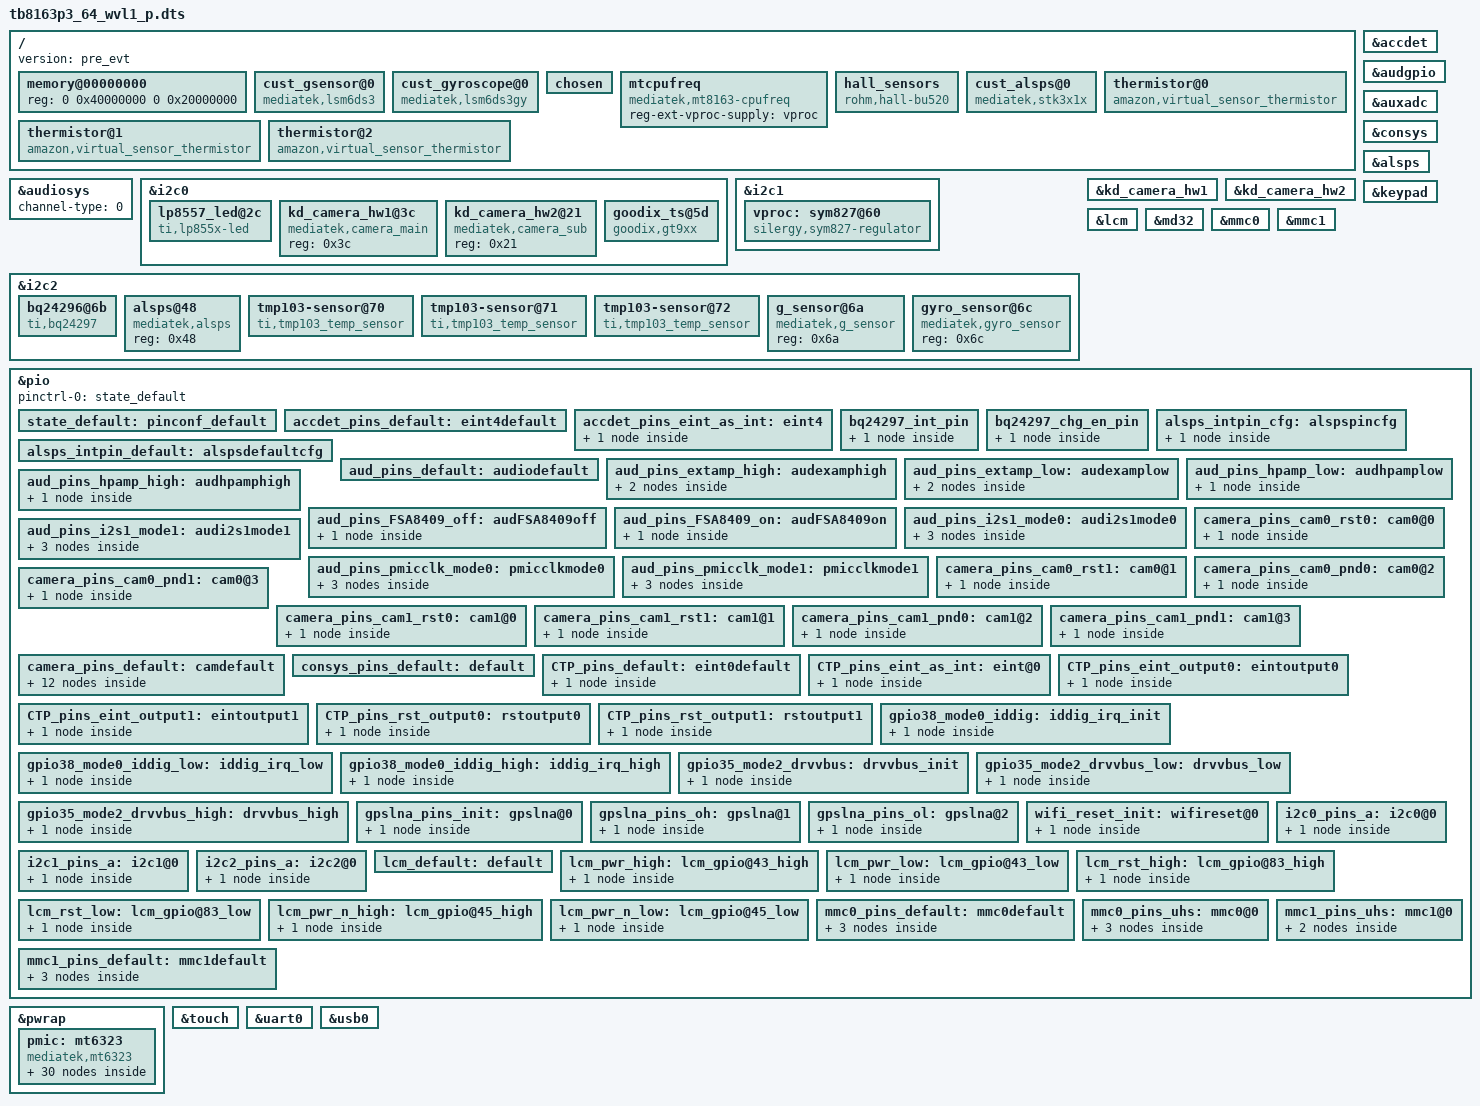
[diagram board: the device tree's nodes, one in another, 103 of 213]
/*
 * Copyright (c) 2014-2015 MediaTek Inc.
 *
 * This program is free software; you can redistribute it and/or modify
 * it under the terms of the GNU General Public License version 2 as
 * published by the Free Software Foundation.
 *
 * This program is distributed in the hope that it will be useful,
 * MERCHANTABILITY or FITNESS FOR A PARTICULAR PURPOSE.  See the
 * GNU General Public License for more details.
 */

/dts-v1/;

#include "mt8163.dtsi"
#include "tb8163p3_64_wvl1_p_bat_setting.dtsi"

/ {
	version = "pre_evt";
	memory@00000000 {
		device_type = "memory";
		reg = <0 0x40000000 0 0x20000000>;
	};

	/* Accel Sensor */
	cust_gsensor@0 {
		compatible = "mediatek,lsm6ds3";
		i2c_num = <2>;
		i2c_addr = <0x6a>;
		direction = <0>;
		power_id = <0xffff>;
		power_vol = <0>;
		firlen = <0>;
		is_batch_supported = <0>;
	};
	
	/* Gyro Sensor */
	cust_gyroscope@0 {
		compatible = "mediatek,lsm6ds3gy";
		i2c_num = <2>;
		i2c_addr = <0x6a>;
		direction = <0>;
		power_id = <0xffff>;
		power_vol = <0>;
		firlen = <0>;
		is_batch_supported = <0>;
	};

	/* chosen */
	chosen {
		bootargs = "console=ttyS0,921600n1 root=/dev/ram initrd=0x44000200,0x200000";
	};

	mtcpufreq {
		compatible = "mediatek,mt8163-cpufreq";
		reg-ext-vproc-supply = <&vproc>;
	};
	/* Hall Sensor */
	hall_sensors {
		compatible = "rohm,hall-bu520";
		interrupt-parent = <&pio>;
		interrupts = <19 IRQ_TYPE_LEVEL_LOW>;
		int-gpio = <&pio 51 0>;
		sensor-name = "hall_sensor_1";
		sensor-num = <1>;
	};
        /* ALS */
        cust_alsps@0 {
		compatible		= "mediatek,stk3x1x";
		i2c_num			= <2>;
		i2c_addr		= <0x48>;
		polling_mode_ps		= <0>;
		polling_mode_als	= <1>;
		power_id		= <0xffff>;
		power_vol		= <0>;
                /* Total has 15 level*/
		als_level	= <0 257 637 1027 2297 5588 6730 11301 20449 25768 31122 45552 57937 57937 57937>;
                /*  Total has 16 range*/
		als_value	= <0 132 304 502 1004 2003 3006 5006 8004 10000 12000 16000 20000 20000 20000 20000>;
		ps_threshold_high	= <70>;
		ps_threshold_low	= <40>;
		is_batch_supported_ps	= <1>;
	};
	/* Virtual sensor thermistor */
	thermistor@0 {
		compatible = "amazon,virtual_sensor_thermistor";
		thermistor,offset = <5250>;
		thermistor,offset.sign = "plus";
		thermistor,alpha = <10>;
		thermistor,weight = <175>;
		aux_channel_num = <0>;
	};
	thermistor@1 {
		compatible = "amazon,virtual_sensor_thermistor";
		thermistor,offset = <2900>;
		thermistor,offset.sign = "plus";
		thermistor,alpha = <10>;
		thermistor,weight = <175>;
		aux_channel_num = <1>;
	};
	thermistor@2 {
		compatible = "amazon,virtual_sensor_thermistor";
		thermistor,offset = <3000>;
		thermistor,offset.sign = "minus";
		thermistor,alpha = <10>;
		thermistor,weight = <175>;
		aux_channel_num = <2>;
	};
};

&accdet {
	interrupt-parent = <&pio>;
	interrupts = <4 IRQ_TYPE_LEVEL_LOW>;
	eint-debounce = <256000>;
	accdet-gpio = <&pio 26 0>;
	accdet-mic-vol = <7>;
	headset-mode-setting = <0x500 0x200 1 0x1f0 0x800 0x800 0x4000>;
	accdet-plugout-debounce = <1000>;
	/*1:ACC mode, 2:low cost without in bias, 6:low cost with in bias*/
	accdet-mic-mode = <1>;
	/*0--MD_MAX--UP_MAX--DW_MAX*/
	headset-three-key-threshold = <0 80 220 500>;
	/*0--MD_MAX--VOICE_MAX--UP_MAX--DW_MAX*/
	headset-four-key-threshold = <0 58 121 192 450>;
	pinctrl-names = "default", "state_eint_as_int", "typeswitchIC-off","typeswitchIC-on";
	pinctrl-0 = <&accdet_pins_default>;
	pinctrl-1 = <&accdet_pins_eint_as_int>;
	pinctrl-2 = <&aud_pins_FSA8409_off>;
	pinctrl-3 = <&aud_pins_FSA8409_on>;
	status = "okay";
};

&audiosys {
	/*0:Stereo, 1:MonoLeft, 2:MonoRight*/
	channel-type = <0>;
};

&audgpio {
	pinctrl-names = "default",
			"audpmicclk-mode0",
			"audpmicclk-mode1",
			"audi2s1-mode0",
			"audi2s1-mode1",
			"extamp-pullhigh",
			"extamp-pulllow",
			"hpamp-pullhigh",
			"hpamp-pulllow";
	pinctrl-0 = <&aud_pins_default>;
	pinctrl-1 = <&aud_pins_pmicclk_mode0>;
	pinctrl-2 = <&aud_pins_pmicclk_mode1>;
	pinctrl-3 = <&aud_pins_i2s1_mode0>;
	pinctrl-4 = <&aud_pins_i2s1_mode1>;
	pinctrl-5 = <&aud_pins_extamp_high>;
	pinctrl-6 = <&aud_pins_extamp_low>;
	pinctrl-7 = <&aud_pins_hpamp_high>;
	pinctrl-8 = <&aud_pins_hpamp_low>;
	status = "okay";
};

&auxadc {
	status = "okay";
};

&consys {
	pinctrl-names = "default",
			"gps_lna_state_init",
			"gps_lna_state_oh",
			"gps_lna_state_ol",
			"wifi_reset_init";
	pinctrl-0 = <&consys_pins_default>;
	pinctrl-1 = <&gpslna_pins_init>;
	pinctrl-2 = <&gpslna_pins_oh>;
	pinctrl-3 = <&gpslna_pins_ol>;
	pinctrl-4 = <&wifi_reset_init>;
	vcn18-supply = <&mt6323_vcn18_reg>;
	vcn28-supply = <&mt6323_vcn28_reg>;
	vcn33_bt-supply = <&mt6323_vcn33_bt_reg>;
	vcn33_wifi-supply = <&mt6323_vcn33_wifi_reg>;
	status = "okay";
};

&alsps {
	pinctrl-names = "pin_default", "pin_cfg";
	pinctrl-0 = <&alsps_intpin_default>;
	pinctrl-1 = <&alsps_intpin_cfg>;
	status = "okay";
};

&i2c0 {
	clock-frequency = <400000>;
	pinctrl-names = "default";
	pinctrl-0 = <&i2c0_pins_a>;
	status = "okay";

	lp8557_led@2c {
		compatible = "ti,lp855x-led";
		reg = <0x2c>;
		epprom_data = /bits/ 8 <0x14 0x07
					0x13 0x01
					0x11 0x05
					0x12 0x2B
					0x15 0x42
					0x16 0xA0>;
	};

	/* in cust_i2c_projXXX.dtsi ? */
	kd_camera_hw1@3c { /* Fix me to right reg val */
		compatible = "mediatek,camera_main";
		reg = <0x3c>;
	};

	/* in cust_i2c_projXXX.dtsi ? */
	kd_camera_hw2@21 { /* Fix me to right reg val */
		compatible = "mediatek,camera_sub";
		reg = <0x21>;
	};

	goodix_ts@5d {
		compatible = "goodix,gt9xx";
		reg = <0x5d>;
		pinctrl-names = "irq_as_gpio", "irq_as_int";
		pinctrl-0 = <&CTP_pins_eint_output0>;
		pinctrl-1 = <&CTP_pins_eint_as_int>;
		vdd_ana-supply = <&mt6323_vgp2_reg>;
		vcc_i2c-supply = <&mt6323_vcamaf_reg>;
		goodix,rst-gpio = <&pio 46 0x00>;
		goodix,irq-gpio = <&pio 35 0x00>;
		goodix,cfg-group0 = [
	 4B  20  03  00  05  0A  35  00  02  08
	 2D  0F  5A  32  01  04  00  00  00  00
	 13  21  00  17  18  1A  14  93  33  CC
	 58  5A  EB  17  00  00  00  22  03  1D
	 00  00  00  00  00  00  00  00  00  00
	 00  50  64  81  E2  01  14  0A  00  04
	 7A  51  00  7D  55  00  81  59  00  85
	 5D  00  8A  61  00  8A  00  00  00  00
	 00  00  00  00  00  00  00  00  00  00
	 00  00  00  00  00  00  14  00  00  00
	 00  00  00  00  00  00  00  00  00  00
	 00  00  17  16  15  14  13  12  11  10
	 0F  0E  0D  0C  0B  0A  09  08  07  06
	 05  04  03  02  01  00  FF  FF  FF  FF
	 FF  FF  00  01  02  03  04  05  06  07
	 08  09  0A  0B  0C  0E  0F  10  11  12
	 13  15  16  17  18  19  1B  1D  1E  1F
	 20  21  22  23  24  25  26  27  28  29
	 FF  FF  FF  FF  32  01];

		goodix,cfg-group2 = [
	 4B  20  03  00  05  0A  35  00  02  08
	 2D  0F  5A  32  01  04  00  00  00  00
	 13  21  00  17  18  1A  14  93  33  CC
	 58  5A  EB  17  00  00  00  22  03  1D
	 00  00  00  00  00  00  00  00  00  00
	 00  50  64  81  E2  01  14  0A  00  04
	 7A  51  00  7D  55  00  81  59  00  85
	 5D  00  8A  61  00  8A  00  00  00  00
	 00  00  00  00  00  00  00  00  00  00
	 00  00  00  00  00  00  14  00  00  00
	 00  00  00  00  00  00  00  00  00  00
	 00  00  17  16  15  14  13  12  11  10
	 0F  0E  0D  0C  0B  0A  09  08  07  06
	 05  04  03  02  01  00  FF  FF  FF  FF
	 FF  FF  00  01  02  03  04  05  06  07
	 08  09  0A  0B  0C  0E  0F  10  11  12
	 13  15  16  17  18  19  1B  1D  1E  1F
	 20  21  22  23  24  25  26  27  28  29
	 FF  FF  FF  FF  32  01];

		goodix,cfg-group3 = [
	 4E  20  03  00  05  0A  35  00  02  08
	 20  0F  50  32  01  04  00  00  00  00
	 13  21  00  17  18  1A  14  93  33  CC
	 58  5A  EB  17  00  00  00  22  03  1D
	 00  00  00  00  00  00  00  00  00  00
	 00  50  64  81  E2  01  14  0A  00  04
	 B7  51  00  BB  55  00  C1  59  00  C7
	 5D  00  CF  61  00  CF  00  00  00  00
	 00  00  00  00  00  00  00  00  00  00
	 00  00  00  00  00  00  20  00  00  00
	 00  00  00  00  00  00  00  00  00  00
	 00  00  17  16  15  14  13  12  11  10
	 0F  0E  0D  0C  0B  0A  09  08  07  06
	 05  04  03  02  01  00  FF  FF  FF  FF
	 FF  FF  29  28  27  26  25  24  23  22
	 21  20  1F  1E  1D  1B  19  18  17  16
	 15  13  12  11  10  0F  0E  0C  0B  0A
	 09  08  07  06  05  04  03  02  01  00
	 FF  FF  FF  FF  B3  01];

		goodix,cfg-group5 = [
	 4E  20  03  00  05  0A  35  00  02  08
	 20  0F  50  32  01  04  00  00  00  00
	 13  21  00  17  18  1A  14  93  33  CC
	 58  5A  EB  17  00  00  00  22  03  1D
	 00  00  00  00  00  00  00  00  00  00
	 00  50  64  81  E2  01  14  0A  00  04
	 B7  51  00  BB  55  00  C1  59  00  C7
	 5D  00  CF  61  00  CF  00  00  00  00
	 00  00  00  00  00  00  00  00  00  00
	 00  00  00  00  00  00  20  00  00  00
	 00  00  00  00  00  00  00  00  00  00
	 00  00  17  16  15  14  13  12  11  10
	 0F  0E  0D  0C  0B  0A  09  08  07  06
	 05  04  03  02  01  00  FF  FF  FF  FF
	 FF  FF  29  28  27  26  25  24  23  22
	 21  20  1F  1E  1D  1B  19  18  17  16
	 15  13  12  11  10  0F  0E  0C  0B  0A
	 09  08  07  06  05  04  03  02  01  00
	 FF  FF  FF  FF  B3  01];

	};

};

&i2c1 {
	clock-frequency = <400000>;
	pinctrl-names = "default";
	pinctrl-0 = <&i2c1_pins_a>;
	status = "okay";

	vproc: sym827@60 {
		compatible = "silergy,sym827-regulator";
		reg = <0x60>;
		regulator-name = "vproc";
		regulator-min-microvolt = <600000>;
		regulator-max-microvolt = <1387500>;
		regulator-enable-ramp-delay = <400>;
		regulator-ramp-delay = <8333>;
		regulator-always-on;
		vsel-gpio = <&pio 34 0>;
	};
};

&i2c2 {
	clock-frequency = <400000>;
	pinctrl-names = "default";
	pinctrl-0 = <&i2c2_pins_a>;
	status = "okay";

	bq24296@6b {
		compatible = "ti,bq24297";
		reg = <0x6b>;
		interrupt-parent = <&pio>;
		interrupts = <1 IRQ_TYPE_EDGE_FALLING>;
		pinctrl-names = "bq24297_chg_en", "bq24297_interrupt_init";
		pinctrl-0 = <&bq24297_chg_en_pin>;
		pinctrl-1 = <&bq24297_int_pin>;
	};

        alsps@48 {
		compatible = "mediatek,alsps";
		reg = <0x48>;
	};

	tmp103-sensor@70 {
		compatible = "ti,tmp103_temp_sensor";
		reg = <0x70>;
		tmp103-sensor,offset = <2300>;
		tmp103-sensor,alpha = <10>;
		tmp103-sensor,weight = <0>;
	};
	tmp103-sensor@71 {
		compatible = "ti,tmp103_temp_sensor";
		reg = <0x71>;
		tmp103-sensor,offset = <750>;
		tmp103-sensor,alpha = <10>;
		tmp103-sensor,weight = <0>;
	};
	tmp103-sensor@72 {
		compatible = "ti,tmp103_temp_sensor";
		reg = <0x72>;
		tmp103-sensor,offset = <750>;
		tmp103-sensor,alpha = <10>;
		tmp103-sensor,weight = <0>;
	};

        /* Accel Sensor */
        g_sensor@6a {
                compatible = "mediatek,g_sensor";
                reg = <0x6a>;
        };

        /* Gyro Sensor */
        gyro_sensor@6c {
                compatible = "mediatek,gyro_sensor";
                reg = <0x6c>;
        };
};

/* Main Cam */
&kd_camera_hw1 {
	reg-vcama-supply = <&mt6323_vcama_reg>;		/* AVDD */
	reg-vcamd-supply = <&mt6323_vcamd_reg>;		/* DVDD */
	reg-vcamio-supply = <&mt6323_vcamio_reg>;	/* DOVDD */
	reg-vcamaf-supply = <&mt6323_vcamaf_reg>;	/* AFVDD */
	reg-vcami2c-supply = <&mt6323_vio18_reg>;	/* I2C */

	pinctrl-names = "default", "cam0_rst0", "cam0_rst1", "cam0_pnd0", "cam0_pnd1",
			"cam1_rst0", "cam1_rst1", "cam1_pnd0", "cam1_pnd1","cam_ldo0_0", "cam_ldo0_1";
	pinctrl-0 = <&camera_pins_default>;
	pinctrl-1 = <&camera_pins_cam0_rst0>;
	pinctrl-2 = <&camera_pins_cam0_rst1>;
	pinctrl-3 = <&camera_pins_cam0_pnd0>;
	pinctrl-4 = <&camera_pins_cam0_pnd1>;
	pinctrl-5 = <&camera_pins_cam1_rst0>;
	pinctrl-6 = <&camera_pins_cam1_rst1>;
	pinctrl-7 = <&camera_pins_cam1_pnd0>;
	pinctrl-8 = <&camera_pins_cam1_pnd1>;
/*
	pinctrl-9 = <&camera_pins_cam_ldo0_0>;
	pinctrl-10 = <&camera_pins_cam_ldo0_1>;
*/
	status = "okay";

};

/* Sub Cam */
/* FIX ME: same power pins as Main ? */
&kd_camera_hw2{
	reg-vcama-supply = <&mt6323_vcama_reg>;		/* AVDD */
	reg-vcamd-supply = <&mt6323_vcamd_reg>;		/* DVDD */
	reg-vcamio-supply = <&mt6323_vcamio_reg>;	/* DOVDD */
	reg-vcamaf-supply = <&mt6323_vcamaf_reg>;	/* AFVDD */
	reg-vcami2c-supply = <&mt6323_vio18_reg>;	/* I2C */
};

&keypad {
	mediatek,kpd-key-debounce = <1024>;
	mediatek,kpd-sw-pwrkey = <116>;
	mediatek,kpd-hw-pwrkey = <8>;
	mediatek,kpd-sw-rstkey  = <114>;
	mediatek,kpd-hw-rstkey = <17>;
	mediatek,kpd-use-extend-type = <0>;
	/*HW Keycode [0~71] -> Linux Keycode*/
	mediatek,kpd-hw-map-num = <72>;
	mediatek,kpd-hw-init-map = <115 0 0 0 0 0 0 0 0 0 0 0 0 0 0 0 0 0 0 0 0 0 0 0
			0 0 0 0 0 0 0 0 0 0 0 0 0 0 0 0 0 0 0 0 0 0 0 0
			0 0 0 0 0 0 0 0 0 0 0 0 0 0 0 0 0 0 0 0 0 0 0 0 >;
	mediatek,kpd-pwrkey-eint-gpio = <0>;
	mediatek,kpd-pwkey-gpio-din  = <0>;
	mediatek,kpd-hw-dl-key0 = <0>;
	mediatek,kpd-hw-dl-key1 = <17>;
	mediatek,kpd-hw-dl-key2 = <8>;
	mediatek,kpd-hw-recovery-key = <0>;
	mediatek,kpd-hw-factory-key  = <17>;
};

&lcm {
	pinctrl-names = "default", "lcm_pwr_high", "lcm_pwr_low", "lcm_rst_high", "lcm_rst_low",
			"lcm_pwr_n_high", "lcm_pwr_n_low";
	pinctrl-0 = <&lcm_default>;
	pinctrl-1 = <&lcm_pwr_high>;
	pinctrl-2 = <&lcm_pwr_low>;
	pinctrl-3 = <&lcm_rst_high>;
	pinctrl-4 = <&lcm_rst_low>;
	pinctrl-5 = <&lcm_pwr_n_high>;
	pinctrl-6 = <&lcm_pwr_n_low>;
	reg-lcm-supply = <&mt6323_vrf18_reg>;
};

&md32 {
	status = "okay";
};

&mmc0 {
	pinctrl-names = "default", "state_uhs";
	pinctrl-0 = <&mmc0_pins_default>;
	pinctrl-1 = <&mmc0_pins_uhs>;
	status = "okay";
	bus-width = <8>;
	latch-ck = <1>;
	max-frequency = <200000000>;
	cap-mmc-highspeed;
	mmc-hs200-1_8v;
	cap-mmc-hw-reset;
	vmmc-supply = <&mt6323_vemc3v3_reg>;
	vqmmc-supply = <&mt6323_vio18_reg>;
	non-removable;
};

&mmc1 {
	pinctrl-names = "default", "state_uhs";
	pinctrl-0 = <&mmc1_pins_default>;
	pinctrl-1 = <&mmc1_pins_uhs>;
	status = "okay";
	bus-width = <4>;
	latch-ck = <1>;
	max-frequency = <200000000>;
	cap-sd-highspeed;
	sd-uhs-sdr50;
	sd-uhs-sdr104;
	cd-gpios = <&pio 49 0>;
	vmmc-supply = <&mt6323_vmch_reg>;
	vqmmc-supply = <&mt6323_vmc_reg>;
};

&pio {
	pinctrl-names = "default";
	pinctrl-0 = <&state_default>;

	state_default:pinconf_default {
	};

	accdet_pins_default: eint4default {
	};

	accdet_pins_eint_as_int: eint4 {
		pins_cmd_dat {
			pins = <MT8163_PIN_26_EINT4__FUNC_GPIO26>;
			bias-disable;
		};
	};

	bq24297_int_pin: bq24297_int_pin {
		pins_cmd_dat {
			pinmux = <MT8163_PIN_23_EINT1__FUNC_GPIO23>;
			input-enable;
			bias-pull-up;
		};
	};

	bq24297_chg_en_pin: bq24297_chg_en_pin {
		pins_cmd_dat {
			pins = <MT8163_PIN_22_EINT0__FUNC_GPIO22>;
			slew-rate = <1>;
			bias-disable;
			output-low;
		};
	};

        alsps_intpin_cfg: alspspincfg {
	        pins_cmd_dat {
			pins = <MT8163_PIN_52_EINT20__FUNC_GPIO52>;
			slew-rate = <0>;
			bias-pull-up = <00>;
		};
	};

	alsps_intpin_default: alspsdefaultcfg {
	};

	aud_pins_default: audiodefault {
	};

	aud_pins_extamp_high: audexamphigh {
		pins_cmd0_dat {
			pins = <MT8163_PIN_28_EINT6__FUNC_GPIO28>;
			slew-rate = <1>;
			output-high;
		};
		pins_cmd1_dat {
			pins = <MT8163_PIN_29_EINT7__FUNC_GPIO29>;
			slew-rate = <1>;
			output-high;
		};
	};

	aud_pins_extamp_low: audexamplow {
		pins_cmd0_dat {
			pins = <MT8163_PIN_28_EINT6__FUNC_GPIO28>;
			slew-rate = <1>;
			output-low;
		};
		pins_cmd1_dat {
			pins = <MT8163_PIN_29_EINT7__FUNC_GPIO29>;
			slew-rate = <1>;
			output-low;
		};
	};

	aud_pins_hpamp_high: audhpamphigh {
		pins_cmd_dat {
			pins = <MT8163_PIN_44_EINT12__FUNC_GPIO44>;
			slew-rate = <1>;
			output-high;
		};
	};

	aud_pins_hpamp_low: audhpamplow {
		pins_cmd_dat {
			pins = <MT8163_PIN_44_EINT12__FUNC_GPIO44>;
			slew-rate = <1>;
			output-low;
		};
	};

	aud_pins_FSA8409_off: audFSA8409off {
		pins_cmd_dat {
			pins = <MT8163_PIN_27_EINT5__FUNC_GPIO27>;
			slew-rate = <1>;
			output-low;
		};
	};

	aud_pins_FSA8409_on: audFSA8409on {
		pins_cmd_dat {
			pins = <MT8163_PIN_27_EINT5__FUNC_GPIO27>;
			slew-rate = <1>;
			output-high;
		};
	};

	aud_pins_i2s1_mode0: audi2s1mode0 {
		pins_cmd0_dat {
			pins = <MT8163_PIN_46_EINT14__FUNC_GPIO46>;
		};
		pins_cmd1_dat {
			pins = <MT8163_PIN_47_EINT15__FUNC_GPIO47>;
		};
		pins_cmd2_dat {
			pins = <MT8163_PIN_48_EINT16__FUNC_GPIO48>;
		};
	};

	aud_pins_i2s1_mode1: audi2s1mode1 {
		pins_cmd0_dat {
			pins = <MT8163_PIN_46_EINT14__FUNC_I2S1_DO>;
		};
		pins_cmd1_dat {
			pins = <MT8163_PIN_47_EINT15__FUNC_I2S1_LRCK>;
		};
		pins_cmd2_dat {
			pins = <MT8163_PIN_48_EINT16__FUNC_I2S1_BCK>;
		};
	};

	aud_pins_pmicclk_mode0: pmicclkmode0 {
		pins_cmd0_dat {
			pins = <MT8163_PIN_7_AUD_CLK_MOSI__FUNC_GPIO7>;
		};
		pins_cmd1_dat {
			pins = <MT8163_PIN_8_AUD_DAT_MISO__FUNC_GPIO8>;
		};
		pins_cmd2_dat {
			pins = <MT8163_PIN_9_AUD_DAT_MOSI__FUNC_GPIO9>;
		};
	};

	aud_pins_pmicclk_mode1: pmicclkmode1 {
		pins_cmd0_dat {
			pins = <MT8163_PIN_7_AUD_CLK_MOSI__FUNC_AUD_CLK_MOSI>;
		};
		pins_cmd1_dat {
			pins = <MT8163_PIN_8_AUD_DAT_MISO__FUNC_AUD_DAT_MISO>;
		};
		pins_cmd2_dat {
			pins = <MT8163_PIN_9_AUD_DAT_MOSI__FUNC_AUD_DAT_MOSI>;
		};
	};

	/* CAMERA GPIO standardization */
	/* Project Dependency : tb8163m1 */
	camera_pins_cam0_rst0: cam0@0 {
		pins_cmd_dat {
			pins = <MT8163_PIN_53_SPI_CS__FUNC_GPIO53>;/*GPIO_CAMERA_CMRST_PIN*/
			slew-rate = <1>; /*direction 0:in, 1:out*/
			output-low;/*direction out used only. output_low or high*/
		};
	};
	camera_pins_cam0_rst1: cam0@1 {
		pins_cmd_dat {
			pins = <MT8163_PIN_53_SPI_CS__FUNC_GPIO53>;/*GPIO_CAMERA_CMRST_PIN*/
			slew-rate = <1>;
			output-high;
		};
	};
	camera_pins_cam0_pnd0: cam0@2 {
		pins_cmd_dat {
			pins = <MT8163_PIN_56_SPI_MO__FUNC_GPIO56>;/*GPIO_CAMERA_CMPDN_PIN*/
			slew-rate = <1>;
			output-low;
		};
	};
	camera_pins_cam0_pnd1: cam0@3 {
		pins_cmd_dat {
			pins = <MT8163_PIN_56_SPI_MO__FUNC_GPIO56>;/*GPIO_CAMERA_CMPDN_PIN*/
			slew-rate = <1>;
			output-high;
		};
	};
	camera_pins_cam1_rst0: cam1@0 {
		pins_cmd_dat {
			pins = <MT8163_PIN_55_SPI_MI__FUNC_GPIO55>;/*GPIO_CAMERA_CMRST1_PIN*/
			slew-rate = <1>; /*direction 0:in, 1:out*/
			output-low;/*direction out used only. output_low or high*/
		};
	};
	camera_pins_cam1_rst1: cam1@1 {
		pins_cmd_dat {
			pins = <MT8163_PIN_55_SPI_MI__FUNC_GPIO55>;/*GPIO_CAMERA_CMRST1_PIN*/
			slew-rate = <1>;
			output-high;
		};
	};
	camera_pins_cam1_pnd0: cam1@2 {
		pins_cmd_dat {
			pins = <MT8163_PIN_54_SPI_CK__FUNC_GPIO54>;/*GPIO_CAMERA_CMPDN1_PIN*/
			slew-rate = <1>;
			output-low;
		};
	};
	camera_pins_cam1_pnd1: cam1@3 {
		pins_cmd_dat {
			pins = <MT8163_PIN_54_SPI_CK__FUNC_GPIO54>;/*GPIO_CAMERA_CMPDN1_PIN*/
			slew-rate = <1>;
			output-high;
		};
	};

/*
	camera_pins_cam_ldo0_0: cam@0 {
		pins_cmd_dat {
			pins = <PINMUX_GPIO68__FUNC_GPIO68>;
			slew-rate = <1>;
			output-low;
		};
	};
	camera_pins_cam_ldo0_1: cam@1 {
		pins_cmd_dat {
			pins = <PINMUX_GPIO68__FUNC_GPIO68>;
			slew-rate = <1>;
			output-high;
		};
	};
*/

	/* Set MCLK Pin default mode */
	camera_pins_default: camdefault {
		pins_cmd0_dat {
			pins = <MT8163_PIN_119_CMMCLK__FUNC_CMMCLK>;	/*MCLK*/
		};
		pins_cmd1_dat {
			pins = <MT8163_PIN_107_RDN2__FUNC_CMDAT8>;
		};
		pins_cmd2_dat {
			pins = <MT8163_PIN_108_RDP2__FUNC_CMDAT9>;
		};
		pins_cmd3_dat {
			pins = <MT8163_PIN_109_RDN3__FUNC_CMDAT4>;
		};
		pins_cmd4_dat {
			pins = <MT8163_PIN_110_RDP3__FUNC_CMDAT5>;
		};
		pins_cmd5_dat {
			pins = <MT8163_PIN_111_RCN_A__FUNC_CMDAT6>;
		};
		pins_cmd6_dat {
			pins = <MT8163_PIN_112_RCP_A__FUNC_CMDAT7>;
		};
		pins_cmd7_dat {
			pins = <MT8163_PIN_113_RDN1_A__FUNC_CMDAT2>;
		};
		pins_cmd8_dat {
			pins = <MT8163_PIN_114_RDP1_A__FUNC_CMDAT3>;
		};
		pins_cmd9_dat {
			pins = <MT8163_PIN_115_RDN0_A__FUNC_CMHSYNC>;
		};
		pins_cmd10_dat {
			pins = <MT8163_PIN_116_RDP0_A__FUNC_CMVSYNC>;
		};
		pins_cmd11_dat {
			pins = <MT8163_PIN_120_CMPCLK__FUNC_CMPCLK>;
		};
	};

	/* CONSYS GPIO Settings - Start */
	consys_pins_default: default {

	};
	/* CONSYS GPIO Settings - End */

	CTP_pins_default: eint0default {
		pins_cmd_dat {
			pins = <MT8163_PIN_35_KPROW2__FUNC_GPIO35>;
			slew-rate = <0>;
			bias-disable;
		};
	};

	CTP_pins_eint_as_int: eint@0 {
		pins_cmd_dat {
			pins = <MT8163_PIN_35_KPROW2__FUNC_GPIO35>;
			slew-rate = <0>;
			bias-disable;
		};
	};

	CTP_pins_eint_output0: eintoutput0 {
		pins_cmd_dat {
			pins = <MT8163_PIN_35_KPROW2__FUNC_GPIO35>;
			slew-rate = <1>;
			output-low;
		};
	};

	CTP_pins_eint_output1: eintoutput1 {
		pins_cmd_dat {
			pins = <MT8163_PIN_35_KPROW2__FUNC_GPIO35>;
			slew-rate = <1>;
			output-high;
		};
	};

	CTP_pins_rst_output0: rstoutput0 {
		pins_cmd_dat {
			pins = <MT8163_PIN_46_EINT14__FUNC_GPIO46>;
			slew-rate = <1>;
			output-low;
		};
	};

	CTP_pins_rst_output1: rstoutput1 {
		pins_cmd_dat {
			pins = <MT8163_PIN_46_EINT14__FUNC_GPIO46>;
			slew-rate = <1>;
			output-high;
		};
	};

/* USB GPIO start */
	gpio38_mode0_iddig: iddig_irq_init {
		pins_cmd_dat {
			pins = <MT8163_PIN_38_KPCOL2__FUNC_GPIO38>;
			bias-pull-up;
		};
	};

	gpio38_mode0_iddig_low: iddig_irq_low {
		pins_cmd_dat {
			pins = <MT8163_PIN_38_KPCOL2__FUNC_GPIO38>;
			bias-pull-down;
		};
	};

	gpio38_mode0_iddig_high: iddig_irq_high {
		pins_cmd_dat {
			pins = <MT8163_PIN_38_KPCOL2__FUNC_GPIO38>;
			bias-pull-up;
		};
	};

	gpio35_mode2_drvvbus: drvvbus_init {
		pins_cmd_dat {
			pins = <MT8163_PIN_35_KPROW2__FUNC_USB_DRVVBUS>;
			slew-rate = <1>;
			bias-pull-up = <00>;
		};
	};

	gpio35_mode2_drvvbus_low: drvvbus_low {
		pins_cmd_dat {
			pins = <MT8163_PIN_35_KPROW2__FUNC_USB_DRVVBUS>;
			slew-rate = <1>;
			output-low;
		};
	};

	gpio35_mode2_drvvbus_high: drvvbus_high {
		pins_cmd_dat {
			pins = <MT8163_PIN_35_KPROW2__FUNC_USB_DRVVBUS>;
			slew-rate = <1>;
			output-high;
		};
	};
/* USB GPIO end */

	/* CONSYS GPIO Settings - Start */
	gpslna_pins_init: gpslna@0 {
		pins_cmd_dat {
			pinmux = <MT8163_PIN_6_PWRAP_SPI0_CSN2__FUNC_GPIO6>;
			slew-rate = <0>;
			bias-disable;
			output-low;
		};
	};

	gpslna_pins_oh: gpslna@1 {
		pins_cmd_dat {
			pinmux = <MT8163_PIN_6_PWRAP_SPI0_CSN2__FUNC_GPIO6>;
			slew-rate = <1>;
			output-high;
		};
	};

	gpslna_pins_ol: gpslna@2 {
		pins_cmd_dat {
			pinmux = <MT8163_PIN_6_PWRAP_SPI0_CSN2__FUNC_GPIO6>;
			slew-rate = <1>;
			output-low;
		};
	};
	/* CONSYS GPIO Settings - End */

	wifi_reset_init: wifireset@0 {
		pins_reset_dat {
			pinmux = <MT8163_PIN_60_WB_RSTB__FUNC_WB_RSTB>,
				<MT8163_PIN_63_WB_SCLK__FUNC_WB_SCLK>,
				<MT8163_PIN_64_WB_SDATA__FUNC_WB_SDATA>,
				<MT8163_PIN_65_WB_SEN__FUNC_WB_SEN>;
			input-enable;
			bias-pull-up;
		};
	};

	i2c0_pins_a: i2c0@0 {
		pins1 {
			pinmux = <MT8163_PIN_75_SDA0__FUNC_SDA0_0>,
				 <MT8163_PIN_76_SCL0__FUNC_SCL0_0>;
			bias-disable;
		};
	};

	i2c1_pins_a: i2c1@0 {
		pins1 {
			pinmux = <MT8163_PIN_57_SDA1__FUNC_SDA1_0>,
				 <MT8163_PIN_58_SCL1__FUNC_SCL1_0>;
			bias-disable;
		};
	};

	i2c2_pins_a: i2c2@0 {
		pins1 {
			pinmux = <MT8163_PIN_77_SDA2__FUNC_SDA2_0>,
				 <MT8163_PIN_78_SCL2__FUNC_SCL2_0>;
			bias-disable;
		};
	};

	lcm_default: default {
	};

	lcm_pwr_high: lcm_gpio@43_high {
		pins_cmd_dat {
			pins = <MT8163_PIN_43_EINT11__FUNC_GPIO43>;
			slew-rate = <1>;
			output-high;
		};
	};

	lcm_pwr_low: lcm_gpio@43_low {
		pins_cmd_dat {
			pins = <MT8163_PIN_43_EINT11__FUNC_GPIO43>;
			slew-rate = <1>;
			output-low;
		};
	};

	lcm_rst_high: lcm_gpio@83_high {
		pins_cmd_dat {
			pins = <MT8163_PIN_83_LCM_RST__FUNC_GPIO83>;
			slew-rate = <1>;
			output-high;
		};
	};

	lcm_rst_low: lcm_gpio@83_low {
		pins_cmd_dat {
			pins = <MT8163_PIN_83_LCM_RST__FUNC_GPIO83>;
			slew-rate = <1>;
			output-low;
		};
	};

	lcm_pwr_n_high: lcm_gpio@45_high {
		pins_cmd_dat {
			pins = <MT8163_PIN_45_EINT13__FUNC_GPIO45>;
			slew-rate = <1>;
			output-high;
		};
	};

	lcm_pwr_n_low: lcm_gpio@45_low {
		pins_cmd_dat {
			pins = <MT8163_PIN_45_EINT13__FUNC_GPIO45>;
			slew-rate = <1>;
			output-low;
		};
	};

	mmc0_pins_default: mmc0default {
		pins_cmd_dat {
			pinmux = <MT8163_PIN_137_MSDC0_DAT0__FUNC_MSDC0_DAT0>,
				<MT8163_PIN_136_MSDC0_DAT1__FUNC_MSDC0_DAT1>,
				<MT8163_PIN_135_MSDC0_DAT2__FUNC_MSDC0_DAT2>,
				<MT8163_PIN_134_MSDC0_DAT3__FUNC_MSDC0_DAT3>,
				<MT8163_PIN_130_MSDC0_DAT4__FUNC_MSDC0_DAT4>,
				<MT8163_PIN_129_MSDC0_DAT5__FUNC_MSDC0_DAT5>,
				<MT8163_PIN_128_MSDC0_DAT6__FUNC_MSDC0_DAT6>,
				<MT8163_PIN_127_MSDC0_DAT7__FUNC_MSDC0_DAT7>,
				<MT8163_PIN_132_MSDC0_CMD__FUNC_MSDC0_CMD>;
			input-enable;
			bias-pull-up;
		};

		pins_clk {
			pinmux = <MT8163_PIN_133_MSDC0_CLK__FUNC_MSDC0_CLK>;
			bias-pull-down;
		};

		pins_rst {
			pinmux = <MT8163_PIN_131_MSDC0_RSTB__FUNC_MSDC0_RSTB>;
			bias-pull-up;
		};
	};

	mmc0_pins_uhs: mmc0@0{
		pins_cmd_dat {
			pinmux = <MT8163_PIN_137_MSDC0_DAT0__FUNC_MSDC0_DAT0>,
				<MT8163_PIN_136_MSDC0_DAT1__FUNC_MSDC0_DAT1>,
				<MT8163_PIN_135_MSDC0_DAT2__FUNC_MSDC0_DAT2>,
				<MT8163_PIN_134_MSDC0_DAT3__FUNC_MSDC0_DAT3>,
				<MT8163_PIN_130_MSDC0_DAT4__FUNC_MSDC0_DAT4>,
				<MT8163_PIN_129_MSDC0_DAT5__FUNC_MSDC0_DAT5>,
				<MT8163_PIN_128_MSDC0_DAT6__FUNC_MSDC0_DAT6>,
				<MT8163_PIN_127_MSDC0_DAT7__FUNC_MSDC0_DAT7>,
				<MT8163_PIN_132_MSDC0_CMD__FUNC_MSDC0_CMD>;
			input-enable;
			drive-strength = <MTK_DRIVE_6mA>;
			bias-pull-up = <MTK_PUPD_SET_R1R0_01>;
		};

		pins_clk {
			pinmux = <MT8163_PIN_133_MSDC0_CLK__FUNC_MSDC0_CLK>;
			drive-strength = <MTK_DRIVE_6mA>;
			bias-pull-down = <MTK_PUPD_SET_R1R0_01>;
		};

		pins_rst {
			pinmux = <MT8163_PIN_131_MSDC0_RSTB__FUNC_MSDC0_RSTB>;
			bias-pull-up;
		};
	};

	mmc1_pins_default: mmc1default {
		pins_cmd_dat {
			pinmux = <MT8163_PIN_123_MSDC1_DAT0__FUNC_MSDC1_DAT0>,
				<MT8163_PIN_124_MSDC1_DAT1__FUNC_MSDC1_DAT1>,
				<MT8163_PIN_125_MSDC1_DAT2__FUNC_MSDC1_DAT2>,
				<MT8163_PIN_126_MSDC1_DAT3__FUNC_MSDC1_DAT3>,
				<MT8163_PIN_121_MSDC1_CMD__FUNC_MSDC1_CMD>;
			input-enable;
			drive-strength = <MTK_DRIVE_6mA>;
			bias-pull-up = <MTK_PUPD_SET_R1R0_01>;
		};

		pins_clk {
			pinmux = <MT8163_PIN_122_MSDC1_CLK__FUNC_MSDC1_CLK>;
			drive-strength = <MTK_DRIVE_6mA>;
			bias-pull-down = <MTK_PUPD_SET_R1R0_10>;
		};

		pins_insert {
			pinmux = <MT8163_PIN_49_EINT17__FUNC_GPIO49>;
			bias-pull-up;
		};
	};

	mmc1_pins_uhs: mmc1@0 {
		pins_cmd_dat {
			pinmux = <MT8163_PIN_123_MSDC1_DAT0__FUNC_MSDC1_DAT0>,
				<MT8163_PIN_124_MSDC1_DAT1__FUNC_MSDC1_DAT1>,
				<MT8163_PIN_125_MSDC1_DAT2__FUNC_MSDC1_DAT2>,
				<MT8163_PIN_126_MSDC1_DAT3__FUNC_MSDC1_DAT3>,
				<MT8163_PIN_121_MSDC1_CMD__FUNC_MSDC1_CMD>;
			input-enable;
			drive-strength = <MTK_DRIVE_8mA>;
			bias-pull-up = <MTK_PUPD_SET_R1R0_10>;
		};

		pins_clk {
			pinmux = <MT8163_PIN_122_MSDC1_CLK__FUNC_MSDC1_CLK>;
			drive-strength = <MTK_DRIVE_8mA>;
			bias-pull-down = <MTK_PUPD_SET_R1R0_10>;
		};
	};
};

&pwrap {
	pmic: mt6323 {
		compatible = "mediatek,mt6323";

		pmicmt6323: pmicmt6323 {
			compatible = "mediatek,mt6323-pmic";
			interrupt-parent = <&pio>;
			interrupts = <24 IRQ_TYPE_LEVEL_HIGH>;
		};

		regulators {

			compatible = "mediatek,mt6323-regulator";

			mt6323_vproc_reg: buck_vproc {
				regulator-name = "vproc";
				regulator-min-microvolt = < 700000>;
				regulator-max-microvolt = <1350000>;
				regulator-ramp-delay = <12500>;
				regulator-always-on;
				regulator-boot-on;
			};

			mt6323_vsys_reg: buck_vsys {
				regulator-name = "vsys";
				regulator-min-microvolt = <1400000>;
				regulator-max-microvolt = <2987500>;
				regulator-ramp-delay = <25000>;
				regulator-always-on;
				regulator-boot-on;
			};

			mt6323_vpa_reg: buck_vpa {
				regulator-name = "vpa";
				regulator-min-microvolt = < 500000>;
				regulator-max-microvolt = <3650000>;
			};

			mt6323_vtcxo_reg: ldo_vtcxo {
				regulator-name = "vtcxo";
				regulator-min-microvolt = <2800000>;
				regulator-max-microvolt = <2800000>;
				regulator-enable-ramp-delay = <90>;
				regulator-always-on;
				regulator-boot-on;
			};

			mt6323_vcn28_reg: ldo_vcn28 {
				regulator-name = "vcn28";
				regulator-min-microvolt = <2800000>;
				regulator-max-microvolt = <2800000>;
				regulator-enable-ramp-delay = <185>;
			};

			mt6323_vcn33_bt_reg: ldo_vcn33_bt {
				regulator-name = "vcn33_bt";
				regulator-min-microvolt = <3300000>;
				regulator-max-microvolt = <3600000>;
				regulator-enable-ramp-delay = <185>;
			};

			mt6323_vcn33_wifi_reg: ldo_vcn33_wifi {
				regulator-name = "vcn33_wifi";
				regulator-min-microvolt = <3300000>;
				regulator-max-microvolt = <3600000>;
				regulator-enable-ramp-delay = <185>;
			};

			mt6323_va_reg: ldo_va {
				regulator-name = "va";
				regulator-min-microvolt = <2800000>;
				regulator-max-microvolt = <2800000>;
				regulator-enable-ramp-delay = <216>;
				regulator-always-on;
				regulator-boot-on;
			};

			mt6323_vcama_reg: ldo_vcama {
				regulator-name = "vcama";
				regulator-min-microvolt = <1500000>;
				regulator-max-microvolt = <2800000>;
				regulator-enable-ramp-delay = <216>;
			};

			mt6323_vio28_reg: ldo_vio28 {
				regulator-name = "vio28";
				regulator-min-microvolt = <2800000>;
				regulator-max-microvolt = <2800000>;
				regulator-enable-ramp-delay = <216>;
				regulator-always-on;
				regulator-boot-on;
			};

			mt6323_vusb_reg: ldo_vusb {
				regulator-name = "vusb";
				regulator-min-microvolt = <3300000>;
				regulator-max-microvolt = <3300000>;
				regulator-enable-ramp-delay = <216>;
				regulator-boot-on;
			};

			mt6323_vmc_reg: ldo_vmc {
				regulator-name = "vmc";
				regulator-min-microvolt = <1800000>;
				regulator-max-microvolt = <3300000>;
				regulator-enable-ramp-delay = <36>;
				regulator-boot-on;
			};

			mt6323_vmch_reg: ldo_vmch {
				regulator-name = "vmch";
				regulator-min-microvolt = <3000000>;
				regulator-max-microvolt = <3300000>;
				regulator-enable-ramp-delay = <36>;
				regulator-boot-on;
			};

			mt6323_vemc3v3_reg: ldo_vemc3v3 {
				regulator-name = "vemc3v3";
				regulator-min-microvolt = <3000000>;
				regulator-max-microvolt = <3300000>;
				regulator-enable-ramp-delay = <36>;
				regulator-boot-on;
			};

			mt6323_vgp1_reg: ldo_vgp1 {
				regulator-name = "vgp1";
				regulator-min-microvolt = <1200000>;
				regulator-max-microvolt = <3300000>;
				regulator-enable-ramp-delay = <216>;
			};

			mt6323_vgp2_reg: ldo_vgp2 {
				regulator-name = "vgp2";
				regulator-min-microvolt = <1200000>;
				regulator-max-microvolt = <3000000>;
				regulator-enable-ramp-delay = <216>;
			};

			mt6323_vgp3_reg: ldo_vgp3 {
				regulator-name = "vgp3";
				regulator-min-microvolt = <1200000>;
				regulator-max-microvolt = <1800000>;
				regulator-enable-ramp-delay = <216>;
			};

			mt6323_vcn18_reg: ldo_vcn18 {
				regulator-name = "vcn18";
				regulator-min-microvolt = <1800000>;
				regulator-max-microvolt = <1800000>;
				regulator-enable-ramp-delay = <216>;
			};

			mt6323_vsim1_reg: ldo_vsim1 {
				regulator-name = "vsim1";
				regulator-min-microvolt = <1800000>;
				regulator-max-microvolt = <3000000>;
				regulator-enable-ramp-delay = <216>;
			};

			mt6323_vsim2_reg: ldo_vsim2 {
				regulator-name = "vsim2";
				regulator-min-microvolt = <1800000>;
				regulator-max-microvolt = <3000000>;
				regulator-enable-ramp-delay = <216>;
			};

			mt6323_vrtc_reg: ldo_vrtc {
				regulator-name = "vrtc";
				regulator-min-microvolt = <2800000>;
				regulator-max-microvolt = <2800000>;
				regulator-always-on;
				regulator-boot-on;
			};

			mt6323_vcamaf_reg: ldo_vcamaf {
				regulator-name = "vcamaf";
				regulator-min-microvolt = <1200000>;
				regulator-max-microvolt = <3300000>;
				regulator-enable-ramp-delay = <216>;
			};

			mt6323_vibr_reg: ldo_vibr {
				regulator-name = "vibr";
				regulator-min-microvolt = <1200000>;
				regulator-max-microvolt = <3300000>;
				regulator-enable-ramp-delay = <36>;
			};

			mt6323_vrf18_reg: ldo_vrf18 {
				regulator-name = "vrf18";
				regulator-min-microvolt = <1825000>;
				regulator-max-microvolt = <1825000>;
				regulator-enable-ramp-delay = <187>;
				regulator-boot-on;
			};

			mt6323_vm_reg: ldo_vm {
				regulator-name = "vm";
				regulator-min-microvolt = <1200000>;
				regulator-max-microvolt = <1800000>;
				regulator-enable-ramp-delay = <216>;
				regulator-always-on;
				regulator-boot-on;
			};

			mt6323_vio18_reg: ldo_vio18 {
				regulator-name = "vio18";
				regulator-min-microvolt = <1800000>;
				regulator-max-microvolt = <1800000>;
				regulator-enable-ramp-delay = <216>;
				regulator-always-on;
				regulator-boot-on;
			};

			mt6323_vcamd_reg: ldo_vcamd {
				regulator-name = "vcamd";
				regulator-min-microvolt = <1200000>;
				regulator-max-microvolt = <1800000>;
				regulator-enable-ramp-delay = <216>;
			};

			mt6323_vcamio_reg: ldo_vcamio {
				regulator-name = "vcamio";
				regulator-min-microvolt = <1800000>;
				regulator-max-microvolt = <1800000>;
				regulator-enable-ramp-delay = <216>;
			};
		};
	};
};

&touch {
	vtouch-supply = <&mt6323_vgp2_reg>;
	tpd-resolution = <720 1280>;
	use-tpd-button = <0>;
	tpd-key-num = <4>;
	tpd-key-local= <139 172 158 0>;
	tpd-key-dim-local = <60 850 50 30 180 850 50 30 300 850 50 30 420 850 50 30>;
	tpd-max-touch-num = <5>;
	tpd-filter-enable = <1>;
	tpd-filter-pixel-density = <124>;
	tpd-filter-custom-prameters = <0 0 0 0 0 0 0 0 0 0 0 0>;
	tpd-filter-custom-speed = <0 0 0>;
	pinctrl-names = "default", "state_eint_as_int", "state_eint_output0", "state_eint_output1",
		"state_rst_output0", "state_rst_output1";
	pinctrl-0 = <&CTP_pins_default>;
	pinctrl-1 = <&CTP_pins_eint_as_int>;
	pinctrl-2 = <&CTP_pins_eint_output0>;
	pinctrl-3 = <&CTP_pins_eint_output1>;
	pinctrl-4 = <&CTP_pins_rst_output0>;
	pinctrl-5 = <&CTP_pins_rst_output1>;
	status = "okay";
};

&uart0 {
	status="okay";
};

&usb0 {
	vusb-supply = <&mt6323_vusb_reg>;
	pinctrl-names = "iddig_irq_init", "iddig_irq_low", "iddig_irq_high", "drvvbus_init", "drvvbus_low", "drvvbus_high";
	pinctrl-0 = <&gpio38_mode0_iddig>;
	pinctrl-1 = <&gpio38_mode0_iddig_low>;
	pinctrl-2 = <&gpio38_mode0_iddig_high>;
	pinctrl-3 = <&gpio35_mode2_drvvbus>;
	pinctrl-4 = <&gpio35_mode2_drvvbus_low>;
	pinctrl-5 = <&gpio35_mode2_drvvbus_high>;
	iddig_gpio = <&pio 38 0>;
	drvvbus_gpio = <&pio 35 0>;
	status = "okay";
};
